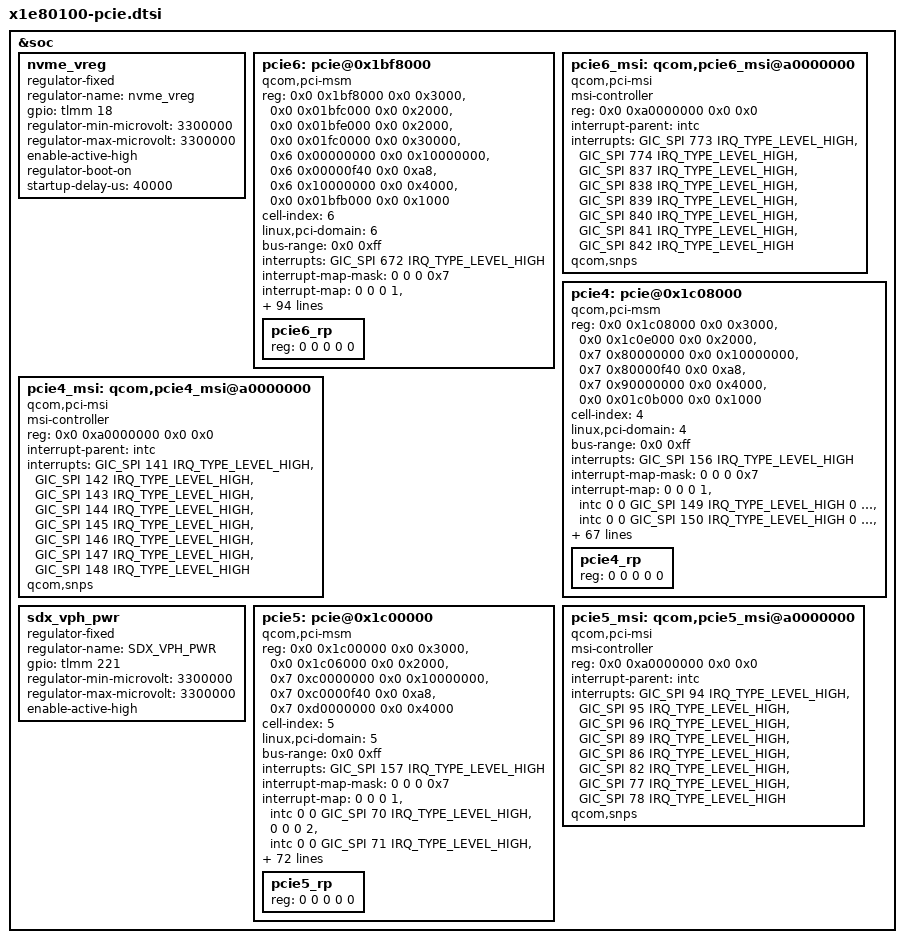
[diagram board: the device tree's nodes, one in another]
// SPDX-License-Identifier: BSD-3-Clause
/*
 * Copyright (c) Qualcomm Technologies, Inc. and/or its subsidiaries.
 */

#include <dt-bindings/gpio/gpio.h>
#include <dt-bindings/clock/qcom,rpmh.h>
#include <dt-bindings/clock/qcom,x1e80100-tcsr.h>
#include <dt-bindings/clock/qcom,x1e80100-gcc.h>

&soc {
	nvme_vreg: nvme_vreg {
		compatible = "regulator-fixed";
		regulator-name = "nvme_vreg";
		gpio = <&tlmm 18 GPIO_ACTIVE_HIGH>;
		regulator-min-microvolt = <3300000>;
		regulator-max-microvolt = <3300000>;
		enable-active-high;
		regulator-boot-on;
		startup-delay-us = <40000>;
	};

	pcie6: pcie@0x1bf8000 {
		compatible = "qcom,pci-msm";

		reg = <0x0 0x1bf8000 0x0 0x3000>,
			<0x0 0x01bfc000 0x0 0x2000>,
			<0x0 0x01bfe000 0x0 0x2000>,
			<0x0 0x01fc0000 0x0 0x30000>,
			<0x6 0x00000000 0x0 0x10000000>,
			<0x6 0x00000f40 0x0 0xa8>,
			<0x6 0x10000000 0x0 0x4000>,
			<0x0 0x01bfb000 0x0 0x1000>;
		reg-names = "parf", "phy", "phy_portb", "tcsr", "dm_core", "elbi", "iatu", "mhi";

		cell-index = <6>;
		linux,pci-domain = <6>;
		bus-range = <0x0 0xff>;

		#address-cells = <3>;
		#size-cells = <2>;
		ranges = <0x01000000 0x0 0x70200000 0x0 0x70200000 0x0 0x100000>,
			<0x02000000 0x0 0x70300000 0x0 0x70300000 0x0 0x3d00000>,
			<0x43000000 0x6 0x10100000 0x6 0x10100000 0x0 0xeff00000>;

		device_type = "pci";
		interrupts = <GIC_SPI 672 IRQ_TYPE_LEVEL_HIGH>;
		interrupt-names = "int_global_int";

		#interrupt-cells = <1>;
		interrupt-map-mask = <0 0 0 0x7>;
		interrupt-map = <0 0 0 1 &intc 0 0 GIC_SPI 843 IRQ_TYPE_LEVEL_HIGH>,
				<0 0 0 2 &intc 0 0 GIC_SPI 844 IRQ_TYPE_LEVEL_HIGH>,
				<0 0 0 3 &intc 0 0 GIC_SPI 845 IRQ_TYPE_LEVEL_HIGH>,
				<0 0 0 4 &intc 0 0 GIC_SPI 772 IRQ_TYPE_LEVEL_HIGH>;

		msi-parent = <&pcie6_msi>;

		perst-gpio = <&tlmm 152 GPIO_ACTIVE_HIGH>;
		wake-gpio = <&tlmm 154 GPIO_ACTIVE_HIGH>;

		pinctrl-names = "init", "default", "sleep";
		pinctrl-0 = <&pcie6_perst_init
				&pcie6_clkreq_default
				&pcie6_wake_default
				&pcie6_nvme_pwr_default>;
		pinctrl-1 = <&pcie6_perst_default
				&pcie6_clkreq_default
				&pcie6_wake_default
				&pcie6_nvme_pwr_default>;
		pinctrl-2 = <&pcie6_perst_default
				&pcie6_clkreq_sleep
				&pcie6_wake_default
				&pcie6_nvme_pwr_sleep>;

		interconnect-names = "icc_path";
		interconnects = <&pcie_south_anoc MASTER_PCIE_6A &mc_virt SLAVE_EBI1>;

		power-domains = <&gcc GCC_PCIE_6A_GDSC>, <&gcc GCC_PCIE_6_PHY_GDSC>;
		power-domain-names = "gdsc-core-vdd", "gdsc-phy-vdd";
		vreg-1p2-supply = <&L2J>;
		vreg-0p9-supply = <&L1D>;
		vreg-qref-supply = <&L3J>;
		vreg-cx-supply = <&VDD_CX_LEVEL>;
		vreg-mx-supply = <&VDD_MXA_LEVEL>;
		vreg-3p3-supply = <&nvme_vreg>;

		/* <max min opt> */
		qcom,vreg-1p2-voltage-level = <1256000 1256000 25000>;
		qcom,vreg-0p9-voltage-level = <880000 880000 410000>;
		qcom,vreg-qref-voltage-level = <880000 880000 1300>;
		qcom,vreg-cx-voltage-level = <RPMH_REGULATOR_LEVEL_MAX
					      RPMH_REGULATOR_LEVEL_LOW_SVS 0>;
		qcom,vreg-mx-voltage-level = <RPMH_REGULATOR_LEVEL_MAX
					      RPMH_REGULATOR_LEVEL_LOW_SVS 0>;

		clocks = <&gcc GCC_PCIE_6A_PIPE_CLK>,
			<&rpmhcc RPMH_CXO_CLK>,
			<&gcc GCC_PCIE_6A_AUX_CLK>,
			<&gcc GCC_PCIE_6A_CFG_AHB_CLK>,
			<&gcc GCC_PCIE_6A_MSTR_AXI_CLK>,
			<&gcc GCC_PCIE_6A_SLV_AXI_CLK>,
			<&tcsrcc TCSR_PCIE_4L_CLKREF_EN>,
			<&gcc GCC_PCIE_6A_SLV_Q2A_AXI_CLK>,
			<&gcc GCC_PCIE_6A_PHY_RCHNG_CLK>,
			<&gcc GCC_CNOC_PCIE_NORTH_SF_AXI_CLK>,
			<&gcc GCC_CNOC_PCIE_SOUTH_SF_AXI_CLK>,
			<&gcc GCC_PCIE_6A_PIPE_CLK_SRC>,
			<&gcc GCC_PCIE_6A_PIPEDIV2_CLK>,
			<&pcie_6a_pipe_clk>,
			<&pcie_6a_phy_aux_clk>,
			<&gcc GCC_PCIE_6A_PHY_AUX_CLK>,
			<&gcc GCC_PCIE_6A_PHY_AUX_CLK_SRC>,
			<&gcc GCC_CFG_NOC_PCIE_ANOC_NORTH_AHB_CLK>,
			<&gcc GCC_CFG_NOC_PCIE_ANOC_SOUTH_AHB_CLK>;
		clock-names = "pcie_pipe_clk", "pcie_ref_clk_src",
			"pcie_aux_clk", "pcie_cfg_ahb_clk",
			"pcie_mstr_axi_clk", "pcie_slv_axi_clk",
			"pcie_clkref_en", "pcie_slv_q2a_axi_clk",
			"pcie_rate_change_clk",
			"gcc_cnoc_pcie_north_sf_axi_clk",
			"gcc_cnoc_pcie_south_sf_axi_clk",
			"pcie_pipe_clk_mux", "pcie_6a_pipe_div2_clk",
			"pcie_pipe_clk_ext_src",
			"pcie_phy_aux_clk_ext_src",
			"pcie_phy_aux_clk",
			"gcc_pcie_6a_phy_aux_clk_src",
			"gcc_cfg_noc_pcie_anoc_north_ahb_clk",
			"gcc_cfg_noc_pcie_anoc_south_ahb_clk";
		qcom,pcie-clock-frequency = <0>, <0>, <19200000>, <0>, <0>, <0>, <0>, <0>,
					    <100000000>, <0>, <0>, <0>, <0>, <0>, <0>, <0>, <0>, <0>, <0>;
		clock-suppressible = <0>, <0>, <0>, <0>, <0>, <0>, <0>, <0>,
				     <0>, <0>, <0>, <0>, <0>, <0>, <0>, <0>, <0>, <0>, <0>;

		qcom,bw-scale = /* Gen1 */
				<RPMH_REGULATOR_LEVEL_LOW_SVS
				RPMH_REGULATOR_LEVEL_LOW_SVS
				19200000
				/* Gen2 */
				RPMH_REGULATOR_LEVEL_LOW_SVS
				RPMH_REGULATOR_LEVEL_LOW_SVS
				19200000
				/* Gen3 */
				RPMH_REGULATOR_LEVEL_LOW_SVS
				RPMH_REGULATOR_LEVEL_LOW_SVS
				100000000
				/* Gen4 */
				RPMH_REGULATOR_LEVEL_LOW_SVS
				RPMH_REGULATOR_LEVEL_LOW_SVS
				100000000>;

		resets = <&gcc GCC_PCIE_6A_BCR>,
			 <&gcc GCC_PCIE_6A_PHY_BCR>;
		reset-names = "pcie_6_core_reset",
			      "pcie_6_phy_reset";

		dma-coherent;

		/* x1e80100 has SMMUv3 */
		iommu-map = <0x0 &pcie_smmu 0x60000 0x1>,
			    <0x100 &pcie_smmu 0x60100 0x1>;


		/* Enable 4-lane capability */
		qcom,bifurcation-capable;

		/* TCSR offset and mask to set for 4-lane mode */
		qcom,tcsr-pcie-link-config-offset = <0x1a000>;
		qcom,tcsr-pcie-link-config-value = <0x1>;
		qcom,tcsr-pcie-link-config-mask = <0x1>;

		qcom,target-link-speed = <0x4>;
		qcom,target-link-width = <0x4>;
		qcom,no-client-based-bw-voting;
		qcom,no-l0s-supported;
		qcom,boot-option = <0x2>;
		qcom,aux-clk-freq = <20>; /* 19.2 MHz */
		qcom,drv-l1ss-timeout-us = <5000>;
		qcom,l1-2-th-scale = <2>;
		qcom,l1-2-th-value = <150>;
		qcom,ep-latency = <10>;
		qcom,num-parf-testbus-sel = <0xb9>;

		qcom,pcie-phy-ver = <105>;
		qcom,phy-sw-reset-offset = <0x1200>;
		qcom,phy-status-offset = <0x1214>;
		qcom,phy-status-bit = <7>;
		qcom,phy-power-down-offset = <0x1240>;
		qcom,phy-start-cntrl-offset = <0x1244>;

		qcom,phy-sequence = <0x10dc 0x1c 0x0
				0x0030 0x1d 0x0
				0x0034 0x03 0x0
				0x0078 0x01 0x0
				0x007c 0x10 0x0
				0x0080 0x51 0x0
				0x00ac 0x34 0x0
				0x0208 0x0c 0x0
				0x0218 0x04 0x0
				0x020c 0x0a 0x0
				0x0220 0x16 0x0
				0x0234 0x00 0x0
				0x029c 0x80 0x0
				0x02a0 0x00 0x0
				0x042c 0x15 0x0
				0x02ac 0x01 0x0
				0x02b0 0x01 0x0
				0x02b4 0x45 0x0
				0x02e8 0x0c 0x0
				0x02e0 0x00 0x0
				0x030c 0x0d 0x0
				0x0320 0x0b 0x0
				0x0348 0x1c 0x0
				0x0388 0x20 0x0
				0x0394 0x38 0x0
				0x03dc 0x39 0x0
				0x03f4 0x14 0x0
				0x03f8 0xb3 0x0
				0x03fc 0x58 0x0
				0x0400 0x9a 0x0
				0x0404 0x38 0x0
				0x0408 0xb6 0x0
				0x040c 0xee 0x0
				0x0410 0xe7 0x0
				0x0414 0xa7 0x0
				0x0418 0x63 0x0
				0x041c 0xdf 0x0
				0x0420 0x4b 0x0
				0x0424 0x76 0x0
				0x0428 0xff 0x0
				0x02d4 0x10 0x0
				0x0830 0x1d 0x0
				0x0834 0x03 0x0
				0x0878 0x01 0x0
				0x087c 0x10 0x0
				0x0880 0x51 0x0
				0x08ac 0x34 0x0
				0x0a08 0x0c 0x0
				0x0a18 0x04 0x0
				0x0a0c 0x0a 0x0
				0x0a20 0x16 0x0
				0x0a34 0x00 0x0
				0x0a9c 0x80 0x0
				0x0aa0 0x00 0x0
				0x0c2c 0x15 0x0
				0x0aac 0x01 0x0
				0x0ab0 0x01 0x0
				0x0ab4 0x45 0x0
				0x0ae8 0x0b 0x0
				0x0ae0 0x00 0x0
				0x0b0c 0x0d 0x0
				0x0b20 0x0b 0x0
				0x0b48 0x1c 0x0
				0x0b88 0x20 0x0
				0x0b94 0x38 0x0
				0x0bdc 0x39 0x0
				0x0bf4 0x14 0x0
				0x0bf8 0xb3 0x0
				0x0bfc 0x58 0x0
				0x0c00 0x9a 0x0
				0x0c04 0x38 0x0
				0x0c08 0xb6 0x0
				0x0c0c 0xee 0x0
				0x0c10 0xe4 0x0
				0x0c14 0xa4 0x0
				0x0c18 0x60 0x0
				0x0c1c 0xdf 0x0
				0x0c20 0x4b 0x0
				0x0c24 0x76 0x0
				0x0c28 0xff 0x0
				0x0ad4 0x10 0x0
				0x0ea0 0x01 0x0
				0x0eb4 0x88 0x0
				0x0ec4 0x02 0x0
				0x0ec8 0x0d 0x0
				0x0ed4 0xd4 0x0
				0x0ed8 0x12 0x0
				0x0edc 0xdb 0x0
				0x0ee0 0x9a 0x0
				0x0ee4 0x32 0x0
				0x0ee8 0xb6 0x0
				0x0eec 0x64 0x0
				0x0ef0 0x1f 0x0
				0x0ef4 0x1f 0x0
				0x0ef8 0x1f 0x0
				0x0efc 0x1f 0x0
				0x0f00 0x1f 0x0
				0x0f04 0x1f 0x0
				0x0f0c 0x1f 0x0
				0x0f14 0x1f 0x0
				0x0f1c 0x1f 0x0
				0x0f28 0x5b 0x0
				0x1000 0x26 0x0
				0x1004 0x03 0x0
				0x1010 0x06 0x0
				0x1014 0x16 0x0
				0x1018 0x36 0x0
				0x101c 0x04 0x0
				0x1020 0x0a 0x0
				0x1024 0x1a 0x0
				0x1028 0x68 0x0
				0x1030 0xab 0x0
				0x1034 0xaa 0x0
				0x1038 0x02 0x0
				0x103c 0x12 0x0
				0x1060 0xf8 0x0
				0x1064 0x01 0x0
				0x1070 0x06 0x0
				0x1074 0x16 0x0
				0x1078 0x36 0x0
				0x107c 0x0a 0x0
				0x1080 0x04 0x0
				0x1084 0x0d 0x0
				0x1088 0x41 0x0
				0x1090 0xab 0x0
				0x1094 0xaa 0x0
				0x1098 0x01 0x0
				0x109c 0x00 0x0
				0x10bc 0x0a 0x0
				0x10c0 0x01 0x0
				0x10cc 0x62 0x0
				0x10d0 0x02 0x0
				0x10d8 0x40 0x0
				0x10e0 0x90 0x0
				0x10e4 0x82 0x0
				0x10f4 0x0f 0x0
				0x1110 0x08 0x0
				0x1120 0x46 0x0
				0x1124 0x04 0x0
				0x1140 0x14 0x0
				0x1164 0x34 0x0
				0x1170 0xa0 0x0
				0x1174 0x06 0x0
				0x1184 0x88 0x0
				0x1188 0x14 0x0
				0x1198 0x0f 0x0
				0x1378 0x2e 0x0
				0x1390 0xaa 0x0
				0x13f8 0x00 0x0
				0x13fc 0x22 0x0
				0x141c 0xc1 0x0
				0x1490 0x00 0x0
				0x14a0 0x16 0x0
				0x1508 0x02 0x0
				0x155c 0x2e 0x0
				0x157c 0x03 0x0
				0x1584 0x28 0x0
				0x158c 0x18 0x0
				0x15ac 0x7a 0x0
				0x15c0 0x8a 0x0
				0x14f0 0x27 0x0
				0x14f4 0x27 0x0
				0x13dc 0x04 0x0
				0x13e0 0x02 0x0
				0x1418 0xc0 0x0
				0x140c 0x1d 0x0
				0x1a38 0x00 0x0
				0x1e38 0x00 0x0
				0x1e24 0x00 0x0
				0x1e28 0x00 0x0 >;

	qcom,phy-sequence-portb = <0x10dc 0x1c 0x0
				0x0030 0x1d 0x0
				0x0034 0x03 0x0
				0x0078 0x01 0x0
				0x007c 0x10 0x0
				0x0080 0x51 0x0
				0x00ac 0x34 0x0
				0x0208 0x0c 0x0
				0x0218 0x04 0x0
				0x020c 0x0a 0x0
				0x0220 0x16 0x0
				0x0234 0x00 0x0
				0x029c 0x80 0x0
				0x02a0 0x00 0x0
				0x042c 0x15 0x0
				0x02ac 0x01 0x0
				0x02b0 0x01 0x0
				0x02b4 0x45 0x0
				0x02e8 0x0c 0x0
				0x02e0 0x00 0x0
				0x030c 0x0d 0x0
				0x0320 0x0b 0x0
				0x0348 0x1c 0x0
				0x0388 0x20 0x0
				0x0394 0x38 0x0
				0x03dc 0x39 0x0
				0x03f4 0x14 0x0
				0x03f8 0xb3 0x0
				0x03fc 0x58 0x0
				0x0400 0x9a 0x0
				0x0404 0x38 0x0
				0x0408 0xb6 0x0
				0x040c 0xee 0x0
				0x0410 0xe7 0x0
				0x0414 0xa7 0x0
				0x0418 0x63 0x0
				0x041c 0xdf 0x0
				0x0420 0x4b 0x0
				0x0424 0x76 0x0
				0x0428 0xff 0x0
				0x02d4 0x10 0x0
				0x0830 0x1d 0x0
				0x0834 0x03 0x0
				0x0878 0x01 0x0
				0x087c 0x10 0x0
				0x0880 0x51 0x0
				0x08ac 0x34 0x0
				0x0a08 0x0c 0x0
				0x0a18 0x04 0x0
				0x0a0c 0x0a 0x0
				0x0a20 0x16 0x0
				0x0a34 0x00 0x0
				0x0a9c 0x80 0x0
				0x0aa0 0x00 0x0
				0x0c2c 0x15 0x0
				0x0aac 0x01 0x0
				0x0ab0 0x01 0x0
				0x0ab4 0x45 0x0
				0x0ae8 0x0b 0x0
				0x0ae0 0x00 0x0
				0x0b0c 0x0d 0x0
				0x0b20 0x0b 0x0
				0x0b48 0x1c 0x0
				0x0b88 0x20 0x0
				0x0b94 0x38 0x0
				0x0bdc 0x39 0x0
				0x0bf4 0x14 0x0
				0x0bf8 0xb3 0x0
				0x0bfc 0x58 0x0
				0x0c00 0x9a 0x0
				0x0c04 0x38 0x0
				0x0c08 0xb6 0x0
				0x0c0c 0xee 0x0
				0x0c10 0xe4 0x0
				0x0c14 0xa4 0x0
				0x0c18 0x60 0x0
				0x0c1c 0xdf 0x0
				0x0c20 0x4b 0x0
				0x0c24 0x76 0x0
				0x0c28 0xff 0x0
				0x0ad4 0x10 0x0
				0x0ea0 0x01 0x0
				0x0eb4 0x88 0x0
				0x0ec4 0x02 0x0
				0x0ec8 0x0d 0x0
				0x0ed4 0xd4 0x0
				0x0ed8 0x12 0x0
				0x0edc 0xdb 0x0
				0x0ee0 0x9a 0x0
				0x0ee4 0x32 0x0
				0x0ee8 0xb6 0x0
				0x0eec 0x64 0x0
				0x0ef0 0x1f 0x0
				0x0ef4 0x1f 0x0
				0x0ef8 0x1f 0x0
				0x0efc 0x1f 0x0
				0x0f00 0x1f 0x0
				0x0f04 0x1f 0x0
				0x0f0c 0x1f 0x0
				0x0f14 0x1f 0x0
				0x0f1c 0x1f 0x0
				0x0f28 0x5b 0x0
				0x1000 0x26 0x0
				0x1004 0x03 0x0
				0x1010 0x06 0x0
				0x1014 0x16 0x0
				0x1018 0x36 0x0
				0x101c 0x04 0x0
				0x1020 0x0a 0x0
				0x1024 0x1a 0x0
				0x1028 0x68 0x0
				0x1030 0xab 0x0
				0x1034 0xaa 0x0
				0x1038 0x02 0x0
				0x103c 0x12 0x0
				0x1060 0xf8 0x0
				0x1064 0x01 0x0
				0x1070 0x06 0x0
				0x1074 0x16 0x0
				0x1078 0x36 0x0
				0x107c 0x0a 0x0
				0x1080 0x04 0x0
				0x1084 0x0d 0x0
				0x1088 0x41 0x0
				0x1090 0xab 0x0
				0x1094 0xaa 0x0
				0x1098 0x01 0x0
				0x109c 0x00 0x0
				0x10bc 0x0a 0x0
				0x10c0 0x01 0x0
				0x10cc 0x62 0x0
				0x10d0 0x02 0x0
				0x10d8 0x40 0x0
				0x10e0 0x90 0x0
				0x10e4 0x82 0x0
				0x10f4 0x0f 0x0
				0x1110 0x08 0x0
				0x1120 0x46 0x0
				0x1124 0x04 0x0
				0x1140 0x14 0x0
				0x1164 0x34 0x0
				0x1170 0xa0 0x0
				0x1174 0x06 0x0
				0x1184 0x88 0x0
				0x1188 0x14 0x0
				0x1198 0x0f 0x0
				0x1378 0x2e 0x0
				0x1390 0xaa 0x0
				0x13f8 0x00 0x0
				0x13fc 0x22 0x0
				0x141c 0xc1 0x0
				0x1490 0x00 0x0
				0x14a0 0x16 0x0
				0x1508 0x02 0x0
				0x155c 0x2e 0x0
				0x157c 0x03 0x0
				0x1584 0x28 0x0
				0x158c 0x18 0x0
				0x15ac 0x7a 0x0
				0x15c0 0x8a 0x0
				0x14f0 0x27 0x0
				0x14f4 0x27 0x0
				0x13dc 0x04 0x0
				0x13e0 0x02 0x0
				0x1418 0xc0 0x0
				0x140c 0x1d 0x0
				0x1a38 0x00 0x0
				0x1e38 0x00 0x0
				0x1e24 0x00 0x0
				0x1e28 0x00 0x0 >;

		status = "okay";

		pcie6_rp: pcie6_rp {
			reg = <0 0 0 0 0>;
		};
	};

	pcie6_msi: qcom,pcie6_msi@a0000000 {
		compatible = "qcom,pci-msi";
		msi-controller;
		reg = <0x0 0xa0000000 0x0 0x0>;
		interrupt-parent = <&intc>;
		interrupts = <GIC_SPI 773 IRQ_TYPE_LEVEL_HIGH>,
				<GIC_SPI 774 IRQ_TYPE_LEVEL_HIGH>,
				<GIC_SPI 837 IRQ_TYPE_LEVEL_HIGH>,
				<GIC_SPI 838 IRQ_TYPE_LEVEL_HIGH>,
				<GIC_SPI 839 IRQ_TYPE_LEVEL_HIGH>,
				<GIC_SPI 840 IRQ_TYPE_LEVEL_HIGH>,
				<GIC_SPI 841 IRQ_TYPE_LEVEL_HIGH>,
				<GIC_SPI 842 IRQ_TYPE_LEVEL_HIGH>;
		qcom,snps;
	};

	pcie4: pcie@0x1c08000 {
		compatible = "qcom,pci-msm";

		reg = <0x0 0x1c08000 0x0 0x3000>,
			<0x0 0x1c0e000 0x0 0x2000>,
			<0x7 0x80000000 0x0 0x10000000>,
			<0x7 0x80000f40 0x0 0xa8>,
			<0x7 0x90000000 0x0 0x4000>,
			<0x0 0x01c0b000 0x0 0x1000>;
		reg-names = "parf", "phy", "dm_core", "elbi", "iatu","mhi";

		cell-index = <4>;
		linux,pci-domain = <4>;
		bus-range = <0x0 0xff>;

		#address-cells = <3>;
		#size-cells = <2>;
		ranges = <0x01000000 0x0 0x7c200000 0x0 0x7c200000 0x0 0x100000>,
			<0x02000000 0x0 0x7c300000 0x0 0x7c300000 0x0 0x1d00000>,
			<0x43000000 0x7 0x90100000 0x7 0x90100000 0x0 0x2ff00000>;

		device_type = "pci";
		interrupts = <GIC_SPI 156 IRQ_TYPE_LEVEL_HIGH>;
		interrupt-names = "int_global_int";

		#interrupt-cells = <1>;
		interrupt-map-mask = <0 0 0 0x7>;

		interrupt-map = <0 0 0 1 &intc 0 0 GIC_SPI 149 IRQ_TYPE_LEVEL_HIGH
				 0 0 0 2 &intc 0 0 GIC_SPI 150 IRQ_TYPE_LEVEL_HIGH
				 0 0 0 3 &intc 0 0 GIC_SPI 151 IRQ_TYPE_LEVEL_HIGH
				 0 0 0 4 &intc 0 0 GIC_SPI 152 IRQ_TYPE_LEVEL_HIGH>;

		msi-parent = <&pcie4_msi>;

		perst-gpio = <&tlmm 146 GPIO_ACTIVE_HIGH>;
		wake-gpio = <&tlmm 148 GPIO_ACTIVE_HIGH>;
		pinctrl-names = "default", "sleep";
		pinctrl-0 = <&pcie4_perst_default
				&pcie4_clkreq_default
				&pcie4_wake_default>;
		pinctrl-1 = <&pcie4_perst_default
				&pcie4_clkreq_sleep
				&pcie4_wake_default>;

		interconnect-names = "icc_path";
		interconnects = <&pcie_north_anoc MASTER_PCIE_4 &mc_virt SLAVE_EBI1>;

		power-domains = <&gcc GCC_PCIE_4_GDSC>, <&gcc GCC_PCIE_4_PHY_GDSC>;
		power-domain-names = "gdsc-core-vdd", "gdsc-phy-vdd";
		vreg-1p2-supply = <&L3E>;
		vreg-0p9-supply = <&L3I>;
		vreg-qref-supply = <&L3J>;
		vreg-cx-supply = <&VDD_CX_LEVEL>;
		vreg-mx-supply = <&VDD_MXA_LEVEL>;
		/* <max min opt> */
		qcom,vreg-1p2-voltage-level = <1200000 1200000 20000>;
		qcom,vreg-0p9-voltage-level = <880000 880000 97000>;
		qcom,vreg-qref-voltage-level = <880000 880000 1300>;
		qcom,vreg-cx-voltage-level = <RPMH_REGULATOR_LEVEL_MAX
						RPMH_REGULATOR_LEVEL_LOW_SVS 0>;
		qcom,vreg-mx-voltage-level = <RPMH_REGULATOR_LEVEL_MAX
						RPMH_REGULATOR_LEVEL_LOW_SVS 0>;
		clocks = <&gcc GCC_PCIE_4_PIPE_CLK>,
			<&rpmhcc RPMH_CXO_CLK>,
			<&gcc GCC_PCIE_4_AUX_CLK>,
			<&gcc GCC_PCIE_4_CFG_AHB_CLK>,
			<&gcc GCC_PCIE_4_MSTR_AXI_CLK>,
			<&gcc GCC_PCIE_4_SLV_AXI_CLK>,
			<&tcsrcc TCSR_PCIE_2L_4_CLKREF_EN>,
			<&gcc GCC_PCIE_4_SLV_Q2A_AXI_CLK>,
			<&gcc GCC_PCIE_4_PHY_RCHNG_CLK>,
			<&gcc GCC_CNOC_PCIE_NORTH_SF_AXI_CLK>,
			<&gcc GCC_CNOC_PCIE_SOUTH_SF_AXI_CLK>,
			<&gcc GCC_PCIE_4_PIPE_CLK_SRC>,
			<&gcc GCC_PCIE_4_PIPEDIV2_CLK>,
			<&gcc GCC_CFG_NOC_PCIE_ANOC_AHB_CLK>,
			<&pcie_4_pipe_clk>;
		clock-names = "pcie_pipe_clk", "pcie_ref_clk_src",
				"pcie_aux_clk", "pcie_cfg_ahb_clk",
				"pcie_mstr_axi_clk", "pcie_slv_axi_clk",
				"pcie_clkref_en", "pcie_slv_q2a_axi_clk",
				"pcie_rate_change_clk", "gcc_cnoc_pcie_north_sf_axi_clk",
				"gcc_cnoc_pcie_south_sf_axi_clk", "pcie_pipe_clk_mux",
				"pcie_4_pipe_div2_clk", "pcie_cfg_noc_pcie_anoc_ahb_clk",
				"pcie_pipe_clk_ext_src";
		qcom,pcie-clock-frequency = <0>, <0>, <19200000>, <0>, <0>, <0>, <0>, <0>,
				<100000000>, <0>, <0>, <0>, <0>, <0>, <0>;
		clock-suppressible = <0>, <0>, <0>, <0>, <0>, <0>, <0>, <0>,
				<0>, <0>, <0>, <0>, <0>, <0>, <0>;

		qcom,bw-scale = /* Gen1 */
				<RPMH_REGULATOR_LEVEL_LOW_SVS
				RPMH_REGULATOR_LEVEL_LOW_SVS
				19200000
				/* Gen2 */
				RPMH_REGULATOR_LEVEL_LOW_SVS
				RPMH_REGULATOR_LEVEL_LOW_SVS
				19200000
				/* Gen3 */
				RPMH_REGULATOR_LEVEL_LOW_SVS
				RPMH_REGULATOR_LEVEL_LOW_SVS
				100000000>;

		resets = <&gcc GCC_PCIE_4_BCR>,
			<&gcc GCC_PCIE_4_PHY_BCR>;
		reset-names = "pcie_4_core_reset",
				"pcie_4_phy_reset";

		dma-coherent;

		/* x1e80100 has SMMUv3 */
		iommu-map = <0x0 &pcie_smmu 0x40000 0x1>,
			    <0x100 &pcie_smmu 0x40100 0x1>;

		qcom,boot-option = <0x1>;
		qcom,aux-clk-freq = <20>; /* 19.2 MHz */
		qcom,drv-l1ss-timeout-us = <5000>;
		qcom,l1-2-th-scale = <2>;
		qcom,l1-2-th-value = <150>;
		qcom,ep-latency = <10>;
		qcom,num-parf-testbus-sel = <0xb9>;
		/* work around to enable ACS quirk */
		qcom,device-vendor-id = <0x011517cb>;

		qcom,pcie-phy-ver = <113>;
		qcom,phy-status-offset = <0x214>;
		qcom,phy-status-bit = <6>;
		qcom,phy-power-down-offset = <0x240>;

		qcom,phy-sequence = <0x0240 0x03 0x0
					0x00c0 0x01 0x0
					0x00cc 0x62 0x0
					0x00d0 0x02 0x0
					0x0060 0xf8 0x0
					0x0064 0x01 0x0
					0x0000 0x93 0x0
					0x0004 0x01 0x0
					0x00e0 0x90 0x0
					0x00e4 0x82 0x0
					0x00f4 0x07 0x0
					0x0070 0x02 0x0
					0x0010 0x02 0x0
					0x0074 0x16 0x0
					0x0014 0x16 0x0
					0x0078 0x36 0x0
					0x0018 0x36 0x0
					0x0110 0x08 0x0
					0x00bc 0x0a 0x0
					0x0120 0x42 0x0
					0x0080 0x04 0x0
					0x0084 0x0d 0x0
					0x0020 0x0a 0x0
					0x0024 0x1a 0x0
					0x0088 0x41 0x0
					0x0028 0x34 0x0
					0x0090 0xab 0x0
					0x0094 0xaa 0x0
					0x0098 0x01 0x0
					0x0030 0x55 0x0
					0x0034 0x55 0x0
					0x0038 0x01 0x0
					0x0140 0x14 0x0
					0x0164 0x34 0x0
					0x003c 0x01 0x0
					0x001c 0x04 0x0
					0x0174 0x16 0x0
					0x01bc 0x0f 0x0
					0x0170 0xa0 0x0
					0x11a4 0x38 0x0
					0x10dc 0x11 0x0
					0x1160 0xbf 0x0
					0x1164 0xbf 0x0
					0x1168 0xb7 0x0
					0x116c 0xea 0x0
					0x115c 0x3f 0x0
					0x1174 0x5c 0x0
					0x1178 0x9c 0x0
					0x117c 0x1a 0x0
					0x1180 0x89 0x0
					0x1170 0xdc 0x0
					0x1188 0x94 0x0
					0x118c 0x5b 0x0
					0x1190 0x1a 0x0
					0x1194 0x89 0x0
					0x10cc 0x00 0x0
					0x1008 0x09 0x0
					0x1014 0x05 0x0
					0x104c 0x08 0x0
					0x1050 0x08 0x0
					0x10d8 0x0f 0x0
					0x1118 0x1c 0x0
					0x10f8 0x07 0x0
					0x11f8 0x08 0x0
					0x1600 0x00 0x0
					0x0e84 0x15 0x0
					0x0e90 0x3f 0x0
					0x0ee4 0x02 0x0
					0x0e40 0x06 0x0
					0x0e3c 0x18 0x0
					0x19a4 0x38 0x0
					0x18dc 0x11 0x0
					0x1960 0xbf 0x0
					0x1964 0xbf 0x0
					0x1968 0xb7 0x0
					0x196c 0xea 0x0
					0x195c 0x3f 0x0
					0x1974 0x5c 0x0
					0x1978 0x9c 0x0
					0x197c 0x1a 0x0
					0x1980 0x89 0x0
					0x1970 0xdc 0x0
					0x1988 0x94 0x0
					0x198c 0x5b 0x0
					0x1990 0x1a 0x0
					0x1994 0x89 0x0
					0x18cc 0x00 0x0
					0x1808 0x09 0x0
					0x1814 0x05 0x0
					0x184c 0x08 0x0
					0x1850 0x08 0x0
					0x18d8 0x0f 0x0
					0x1918 0x1c 0x0
					0x18f8 0x07 0x0
					0x19f8 0x08 0x0
					0x1684 0x15 0x0
					0x1690 0x3f 0x0
					0x16e4 0x02 0x0
					0x1640 0x06 0x0
					0x163c 0x18 0x0
					0x02dc 0x05 0x0
					0x0388 0x77 0x0
					0x0398 0x0b 0x0
					0x06a4 0x1e 0x0
					0x06f4 0x27 0x0
					0x03e0 0x0f 0x0
					0x060c 0x1d 0x0
					0x0614 0x07 0x0
					0x0620 0xc1 0x0
					0x0694 0x00 0x0
					0x03d0 0x8c 0x0
					0x0368 0x17 0x0
					0x0370 0x2e 0x0
					0x1424 0x00 0x0
					0x1428 0x00 0x0
					0x0200 0x00 0x0
					0x0244 0x03 0x0>;

		status = "okay";

		pcie4_rp: pcie4_rp {
			reg = <0 0 0 0 0>;
		};
	};

	pcie4_msi: qcom,pcie4_msi@a0000000 {
		compatible = "qcom,pci-msi";
		msi-controller;
		reg = <0x0 0xa0000000 0x0 0x0>;
		interrupt-parent = <&intc>;
		interrupts = <GIC_SPI 141 IRQ_TYPE_LEVEL_HIGH>,
				<GIC_SPI 142 IRQ_TYPE_LEVEL_HIGH>,
				<GIC_SPI 143 IRQ_TYPE_LEVEL_HIGH>,
				<GIC_SPI 144 IRQ_TYPE_LEVEL_HIGH>,
				<GIC_SPI 145 IRQ_TYPE_LEVEL_HIGH>,
				<GIC_SPI 146 IRQ_TYPE_LEVEL_HIGH>,
				<GIC_SPI 147 IRQ_TYPE_LEVEL_HIGH>,
				<GIC_SPI 148 IRQ_TYPE_LEVEL_HIGH>;
		qcom,snps;
	};

	sdx_vph_pwr: sdx_vph_pwr {
		compatible = "regulator-fixed";
		regulator-name = "SDX_VPH_PWR";
		gpio = <&tlmm 221 GPIO_ACTIVE_HIGH>;
		regulator-min-microvolt = <3300000>;
		regulator-max-microvolt = <3300000>;
		enable-active-high;
	};

	pcie5: pcie@0x1c00000 {
		compatible = "qcom,pci-msm";

		 reg = <0x0 0x1c00000 0x0 0x3000>,
			<0x0 0x1c06000 0x0 0x2000>,
			<0x7 0xc0000000 0x0 0x10000000>,
			<0x7 0xc0000f40 0x0 0xa8>,
			<0x7 0xd0000000 0x0 0x4000>;
		reg-names = "parf", "phy", "dm_core", "elbi", "iatu";

		cell-index = <5>;
		linux,pci-domain = <5>;
		bus-range = <0x0 0xff>;

		#address-cells = <3>;
		#size-cells = <2>;

		ranges = <0x01000000 0x0 0x7e200000 0x0 0x7e200000 0x0 0x100000>,
			<0x02000000 0x0 0x7e300000 0x0 0x7e300000 0x0 0x1d00000>,
			<0x43000000 0x7 0xd0100000 0x7 0xd0100000 0x0 0x2ff00000>;

		device_type = "pci";
		interrupts = <GIC_SPI 157 IRQ_TYPE_LEVEL_HIGH>;
		interrupt-names = "int_global_int";

		#interrupt-cells = <1>;
		interrupt-map-mask = <0 0 0 0x7>;
		interrupt-map = <0 0 0 1 &intc 0 0 GIC_SPI 70 IRQ_TYPE_LEVEL_HIGH>,
				<0 0 0 2 &intc 0 0 GIC_SPI 71 IRQ_TYPE_LEVEL_HIGH>,
				<0 0 0 3 &intc 0 0 GIC_SPI 72 IRQ_TYPE_LEVEL_HIGH>,
				<0 0 0 4 &intc 0 0 GIC_SPI 73 IRQ_TYPE_LEVEL_HIGH>;

		msi-parent = <&pcie5_msi>;

		perst-gpio = <&tlmm 149 GPIO_ACTIVE_HIGH>;
		wake-gpio = <&tlmm 151 GPIO_ACTIVE_HIGH>;
		pinctrl-names = "default", "sleep";
		pinctrl-0 = <&pcie5_perst_default
				&pcie5_clkreq_default
				&pcie5_wake_default
				&sdx_vph_pwr_en>;
		pinctrl-1 = <&pcie5_perst_default
				&pcie5_clkreq_sleep
				&pcie5_wake_default
				&sdx_vph_pwr_sleep>;

		interconnect-names = "icc_path";
		interconnects = <&pcie_north_anoc MASTER_PCIE_5 &mc_virt SLAVE_EBI1>;

		power-domains = <&gcc GCC_PCIE_5_GDSC>, <&gcc GCC_PCIE_5_PHY_GDSC>;
		power-domain-names = "gdsc-core-vdd", "gdsc-phy-vdd";
		vreg-1p2-supply = <&L3E>;
		vreg-0p9-supply = <&L3I>;
		vreg-qref-supply = <&L3J>;
		vreg-cx-supply = <&VDD_CX_LEVEL>;
		vreg-mx-supply = <&VDD_MXA_LEVEL>;

		qcom,vreg-1p2-voltage-level = <1200000 1200000 20000>;
		qcom,vreg-0p9-voltage-level = <880000 880000 97000>;
		qcom,vreg-qref-voltage-level = <880000 880000 1300>;
		qcom,vreg-cx-voltage-level = <RPMH_REGULATOR_LEVEL_MAX
						RPMH_REGULATOR_LEVEL_LOW_SVS 0>;
		qcom,vreg-mx-voltage-level = <RPMH_REGULATOR_LEVEL_MAX
						RPMH_REGULATOR_LEVEL_LOW_SVS 0>;
		clocks = <&gcc GCC_PCIE_5_PIPE_CLK>,
			<&rpmhcc RPMH_CXO_CLK>,
			<&gcc GCC_PCIE_5_AUX_CLK>,
			<&gcc GCC_PCIE_5_CFG_AHB_CLK>,
			<&gcc GCC_PCIE_5_MSTR_AXI_CLK>,
			<&gcc GCC_PCIE_5_SLV_AXI_CLK>,
			<&tcsrcc TCSR_PCIE_2L_5_CLKREF_EN>,
			<&gcc GCC_PCIE_5_SLV_Q2A_AXI_CLK>,
			<&gcc GCC_PCIE_5_PHY_RCHNG_CLK>,
			<&gcc GCC_CNOC_PCIE_NORTH_SF_AXI_CLK>,
			<&gcc GCC_CNOC_PCIE_SOUTH_SF_AXI_CLK>,
			<&gcc GCC_PCIE_5_PIPE_CLK_SRC>,
			<&gcc GCC_PCIE_5_PIPEDIV2_CLK>,
			<&gcc GCC_CFG_NOC_PCIE_ANOC_NORTH_AHB_CLK>,
			<&gcc GCC_CFG_NOC_PCIE_ANOC_AHB_CLK>,
			<&pcie_5_pipe_clk>;
		clock-names = "pcie_pipe_clk", "pcie_ref_clk_src",
				"pcie_aux_clk", "pcie_cfg_ahb_clk",
				"pcie_mstr_axi_clk", "pcie_slv_axi_clk",
				"pcie_clkref_en", "pcie_slv_q2a_axi_clk",
				"pcie_rate_change_clk","gcc_cnoc_pcie_north_sf_axi_clk",
				"gcc_cnoc_pcie_south_sf_axi_clk","pcie_pipe_clk_mux",
				"pcie_5_pipe_div2_clk","gcc_cfg_noc_pcie_anoc_north_ahb_clk",
				"pcie_cfg_noc_pcie_anoc_ahb_clk","pcie_pipe_clk_ext_src";
		qcom,pcie-clock-frequency = <0>, <0>, <19200000>, <0>, <0>, <0>, <0>, <0>,
				<100000000>, <0>, <0>, <0>, <0>, <0>, <0>, <0>;
		clock-suppressible = <0>, <0>, <0>, <0>, <0>, <0>, <0>, <0>,
				<0>, <0>, <0>, <0>, <0>, <0>, <0>, <0>;

		qcom,bw-scale = /* Gen1 */
				<RPMH_REGULATOR_LEVEL_LOW_SVS
				RPMH_REGULATOR_LEVEL_LOW_SVS
				19200000
				/* Gen2 */
				RPMH_REGULATOR_LEVEL_LOW_SVS
				RPMH_REGULATOR_LEVEL_LOW_SVS
				19200000
				/* Gen3 */
				RPMH_REGULATOR_LEVEL_LOW_SVS
				RPMH_REGULATOR_LEVEL_LOW_SVS
				100000000>;

		resets = <&gcc GCC_PCIE_5_BCR>,
			<&gcc GCC_PCIE_5_PHY_BCR>;
		reset-names = "pcie_5_core_reset",
				"pcie_5_phy_reset";

		dma-coherent;

		iommu-map = <0x0 &pcie_smmu 0x50000 0x1>,
			    <0x100 &pcie_smmu 0x50100 0x1>;

		qcom,target-link-speed = <0x3>;
		qcom,boot-option = <0x2>;
		qcom,aux-clk-freq = <20>;
		qcom,drv-l1ss-timeout-us = <5000>;
		qcom,l1-2-th-scale = <2>;
		qcom,l1-2-th-value = <150>;
		qcom,ep-latency = <10>;
		qcom,num-parf-testbus-sel = <0xb9>;

		qcom,pcie-phy-ver = <116>;
		qcom,phy-status-offset = <0x214>;
		qcom,phy-status-bit = <6>;
		qcom,phy-power-down-offset = <0x240>;

		qcom,phy-sequence = <0x0240 0x03 0x0
					0x00c0 0x01 0x0
					0x00cc 0x62 0x0
					0x00d0 0x02 0x0
					0x0060 0xf8 0x0
					0x0064 0x01 0x0
					0x0000 0x93 0x0
					0x0004 0x01 0x0
					0x00e0 0x90 0x0
					0x00e4 0x82 0x0
					0x00f4 0x07 0x0
					0x0070 0x02 0x0
					0x0010 0x02 0x0
					0x0074 0x16 0x0
					0x0014 0x16 0x0
					0x0078 0x36 0x0
					0x0018 0x36 0x0
					0x0110 0x08 0x0
					0x00bc 0x0a 0x0
					0x0120 0x42 0x0
					0x0080 0x04 0x0
					0x0084 0x0d 0x0
					0x0020 0x0a 0x0
					0x0024 0x1a 0x0
					0x0088 0x41 0x0
					0x0028 0x34 0x0
					0x0090 0xab 0x0
					0x0094 0xaa 0x0
					0x0098 0x01 0x0
					0x0030 0x55 0x0
					0x0034 0x55 0x0
					0x0038 0x01 0x0
					0x0140 0x14 0x0
					0x0164 0x34 0x0
					0x003c 0x01 0x0
					0x001c 0x04 0x0
					0x0174 0x16 0x0
					0x01bc 0x0f 0x0
					0x0170 0xa0 0x0
					0x11a4 0x38 0x0
					0x10dc 0x11 0x0
					0x1160 0xbf 0x0
					0x1164 0xbf 0x0
					0x1168 0xb7 0x0
					0x116c 0xea 0x0
					0x115c 0x3f 0x0
					0x1174 0x5c 0x0
					0x1178 0x9c 0x0
					0x117c 0x1a 0x0
					0x1180 0x89 0x0
					0x1170 0xdc 0x0
					0x1188 0x94 0x0
					0x118c 0x5b 0x0
					0x1190 0x1a 0x0
					0x1194 0x89 0x0
					0x10cc 0x00 0x0
					0x1008 0x09 0x0
					0x1014 0x05 0x0
					0x104c 0x08 0x0
					0x1050 0x08 0x0
					0x10d8 0x0f 0x0
					0x1118 0x1c 0x0
					0x10f8 0x07 0x0
					0x11f8 0x08 0x0
					0x1600 0x00 0x0
					0x0e84 0x15 0x0
					0x0e90 0x3f 0x0
					0x0ee4 0x02 0x0
					0x0e40 0x06 0x0
					0x0e3c 0x18 0x0
					0x19a4 0x38 0x0
					0x18dc 0x11 0x0
					0x1960 0xbf 0x0
					0x1964 0xbf 0x0
					0x1968 0xb7 0x0
					0x196c 0xea 0x0
					0x195c 0x3f 0x0
					0x1974 0x5c 0x0
					0x1978 0x9c 0x0
					0x197c 0x1a 0x0
					0x1980 0x89 0x0
					0x1970 0xdc 0x0
					0x1988 0x94 0x0
					0x198c 0x5b 0x0
					0x1990 0x1a 0x0
					0x1994 0x89 0x0
					0x18cc 0x00 0x0
					0x1808 0x09 0x0
					0x1814 0x05 0x0
					0x184c 0x08 0x0
					0x1850 0x08 0x0
					0x18d8 0x0f 0x0
					0x1918 0x1c 0x0
					0x18f8 0x07 0x0
					0x19f8 0x08 0x0
					0x1684 0x15 0x0
					0x1690 0x3f 0x0
					0x16e4 0x02 0x0
					0x1640 0x06 0x0
					0x163c 0x18 0x0
					0x02dc 0x05 0x0
					0x0388 0x77 0x0
					0x0398 0x0b 0x0
					0x06a4 0x1e 0x0
					0x06f4 0x27 0x0
					0x03e0 0x0f 0x0
					0x060c 0x1d 0x0
					0x0614 0x07 0x0
					0x0620 0xc1 0x0
					0x0694 0x00 0x0
					0x03d0 0x8c 0x0
					0x0368 0x17 0x0
					0x0370 0x2e 0x0
					0x1424 0x00 0x0
					0x1428 0x00 0x0
					0x0200 0x00 0x0
					0x0244 0x03 0x0>;

		status = "okay";

		pcie5_rp: pcie5_rp {
			reg = <0 0 0 0 0>;
		};
	};

	pcie5_msi: qcom,pcie5_msi@a0000000 {
		compatible = "qcom,pci-msi";
		msi-controller;
		reg = <0x0 0xa0000000 0x0 0x0>;
		interrupt-parent = <&intc>;
		interrupts = <GIC_SPI 94 IRQ_TYPE_LEVEL_HIGH>,
				<GIC_SPI 95 IRQ_TYPE_LEVEL_HIGH>,
				<GIC_SPI 96 IRQ_TYPE_LEVEL_HIGH>,
				<GIC_SPI 89 IRQ_TYPE_LEVEL_HIGH>,
				<GIC_SPI 86 IRQ_TYPE_LEVEL_HIGH>,
				<GIC_SPI 82 IRQ_TYPE_LEVEL_HIGH>,
				<GIC_SPI 77 IRQ_TYPE_LEVEL_HIGH>,
				<GIC_SPI 78 IRQ_TYPE_LEVEL_HIGH>;
		qcom,snps;
	};

};
